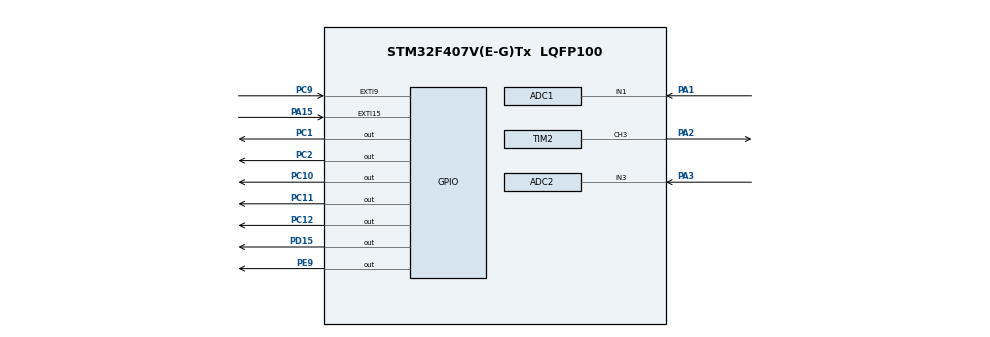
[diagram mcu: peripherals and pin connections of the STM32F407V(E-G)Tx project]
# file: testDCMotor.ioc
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ADC1.Channel-2\#ChannelRegularConversion=ADC_CHANNEL_1
ADC1.NbrOfConversionFlag=1
ADC1.Rank-2\#ChannelRegularConversion=1
ADC1.SamplingTime-2\#ChannelRegularConversion=ADC_SAMPLETIME_28CYCLES
ADC1.master=1
ADC2.Channel-0\#ChannelRegularConversion=ADC_CHANNEL_3
ADC2.NbrOfConversionFlag=1
ADC2.Rank-0\#ChannelRegularConversion=1
ADC2.SamplingTime-0\#ChannelRegularConversion=ADC_SAMPLETIME_28CYCLES
Mcu.Family=STM32F4
Mcu.Name=STM32F407V(E-G)Tx
Mcu.Package=LQFP100
NVIC.EXTI15_10_IRQn=true\:0\:0\:false\:false\:true\:true\:true\:true
NVIC.EXTI9_5_IRQn=true\:0\:0\:false\:false\:true\:true\:true\:true
NVIC.PriorityGroup=NVIC_PRIORITYGROUP_4
PA1.Signal=ADCx_IN1
PA15.GPIO_ModeDefaultEXTI=GPIO_MODE_IT_FALLING
PA15.GPIO_PuPd=GPIO_PULLUP
PA15.Signal=GPXTI15
PA2.Signal=S_TIM2_CH3
PA3.Signal=ADCx_IN3
PC1.GPIO_PuPd=GPIO_PULLDOWN
PC1.GPIO_Speed=GPIO_SPEED_FREQ_HIGH
PC1.PinState=GPIO_PIN_RESET
PC1.Signal=GPIO_Output
PC10.Signal=GPIO_Output
PC11.Signal=GPIO_Output
PC12.Signal=GPIO_Output
PC2.GPIO_PuPd=GPIO_PULLDOWN
PC2.GPIO_Speed=GPIO_SPEED_FREQ_HIGH
PC2.PinState=GPIO_PIN_RESET
PC2.Signal=GPIO_Output
PC9.GPIO_ModeDefaultEXTI=GPIO_MODE_IT_FALLING
PC9.GPIO_PuPd=GPIO_PULLUP
PC9.Signal=GPXTI9
PD15.Signal=GPIO_Output
PE9.GPIO_PuPd=GPIO_PULLDOWN
PE9.GPIO_Speed=GPIO_SPEED_FREQ_HIGH
PE9.PinState=GPIO_PIN_RESET
PE9.Signal=GPIO_Output
ProjectManager.HeapSize=0x200
ProjectManager.StackSize=0x400
ProjectManager.TargetToolchain=STM32CubeIDE
RCC.48MHZClocksFreq_Value=42000000
RCC.AHBFreq_Value=84000000
RCC.APB1CLKDivider=RCC_HCLK_DIV2
RCC.APB1Freq_Value=42000000
RCC.APB1TimFreq_Value=84000000
RCC.APB2Freq_Value=84000000
RCC.APB2TimFreq_Value=84000000
RCC.CortexFreq_Value=84000000
RCC.HCLKFreq_Value=84000000
RCC.HSE_VALUE=25000000
RCC.HSI_VALUE=16000000
RCC.LSE_VALUE=32768
RCC.PLLM=8
RCC.PLLN=84
RCC.SYSCLKFreq_VALUE=84000000
RCC.SYSCLKSource=RCC_SYSCLKSOURCE_PLLCLK
RCC.VCOOutputFreq_Value=168000000
SH.ADCx_IN1.0=ADC1_IN1,IN1
SH.ADCx_IN3.0=ADC2_IN3,IN3
SH.S_TIM2_CH3.0=TIM2_CH3,PWM Generation3 CH3
TIM2.Channel-PWM\ Generation3\ CH3=TIM_CHANNEL_3
TIM2.Period=128
TIM2.Prescaler=84
TIM3.Prescaler=100
VP_TIM3_VS_ClockSourceINT.Mode=Internal
board=custom

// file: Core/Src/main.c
/* USER CODE BEGIN Header */
/**
  ******************************************************************************
  * @file           : main.c
  * @brief          : Main program body
  ******************************************************************************
  * @attention
  *
  * Copyright (c) 2022 STMicroelectronics.
  * All rights reserved.
  *
  * This software is licensed under terms that can be found in the LICENSE file
  * in the root directory of this software component.
  * If no LICENSE file comes with this software, it is provided AS-IS.
  *
  ******************************************************************************
  */
/* USER CODE END Header */
#include "main.h"
#include "adc.h"
#include "tim.h"
#include "gpio.h"

void SystemClock_Config(void);

int main(void)
{

  /* MCU Configuration--------------------------------------------------------*/

  /* Reset of all peripherals, Initializes the Flash interface and the Systick. */
  HAL_Init();

  /* Configure the system clock */
  SystemClock_Config();

  /* Initialize all configured peripherals */
  MX_GPIO_Init();
  MX_TIM2_Init();
  MX_ADC1_Init();
  MX_ADC2_Init();
  MX_TIM3_Init();
  /* USER CODE BEGIN 2 */
  LL_TIM_CC_EnableChannel(TIM2, LL_TIM_CHANNEL_CH3);
  LL_TIM_EnableCounter(TIM2);
  LL_TIM_OC_SetCompareCH3(TIM2, 64);
  /* USER CODE END 2 */

  /* Infinite loop */
  while (1)
  {

  }
}

void SystemClock_Config(void)
{
  LL_FLASH_SetLatency(LL_FLASH_LATENCY_2);
  while(LL_FLASH_GetLatency()!= LL_FLASH_LATENCY_2)
  {
  }
  LL_PWR_SetRegulVoltageScaling(LL_PWR_REGU_VOLTAGE_SCALE1);
  LL_RCC_HSI_SetCalibTrimming(16);
  LL_RCC_HSI_Enable();

   /* Wait till HSI is ready */
  while(LL_RCC_HSI_IsReady() != 1)
  {

  }
  LL_RCC_PLL_ConfigDomain_SYS(LL_RCC_PLLSOURCE_HSI, LL_RCC_PLLM_DIV_8, 84, LL_RCC_PLLP_DIV_2);
  LL_RCC_PLL_Enable();

   /* Wait till PLL is ready */
  while(LL_RCC_PLL_IsReady() != 1)
  {

  }
  LL_RCC_SetAHBPrescaler(LL_RCC_SYSCLK_DIV_1);
  LL_RCC_SetAPB1Prescaler(LL_RCC_APB1_DIV_2);
  LL_RCC_SetAPB2Prescaler(LL_RCC_APB2_DIV_1);
  LL_RCC_SetSysClkSource(LL_RCC_SYS_CLKSOURCE_PLL);

   /* Wait till System clock is ready */
  while(LL_RCC_GetSysClkSource() != LL_RCC_SYS_CLKSOURCE_STATUS_PLL)
  {

  }
  LL_SetSystemCoreClock(84000000);

   /* Update the time base */
  if (HAL_InitTick (TICK_INT_PRIORITY) != HAL_OK)
  {
    Error_Handler();
  }
}

void Error_Handler(void)
{
  __disable_irq();
  while (1)
  {
  }
}
